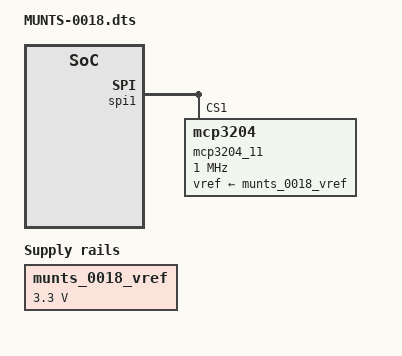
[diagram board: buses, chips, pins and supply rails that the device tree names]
// Device tree overlay for the MUNTS-0018 Raspberry Pi Tutorial I/O Board
// attached to an Orange Pi Zero 2 W.

/dts-v1/;
/plugin/;

/ {
	compatible = "xunlong,orangepi-zero2w";

	// Create a fictitious voltage regulator for the MCP3204 reference

	fragment@0 {
		target-path = "/";
		__overlay__ {
			munts_0018_vref: munts-0018-vref {
				compatible = "regulator-fixed";
				regulator-name = "munts_0018_vref";
				regulator-min-microvolt = <3300000>;
				regulator-max-microvolt = <3300000>;
				regulator-always-on;
				status = "okay";
 			};
		};
	};

	// Enable MCP3204 on SPI chip 1 slave select 0 (GPIO233 aka GPIO7)

	fragment@1 {
		target = <&spi1>;
		__overlay__ {
			#address-cells = <1>;
			#size-cells = <0>;
			status = "okay";

			mcp3204_11: mcp3204@1 {
				compatible = "mcp3204";
				reg = <1>;
				spi-max-frequency = <1000000>;
				vref-supply = <&munts_0018_vref>;
			};
		};
	};
};
